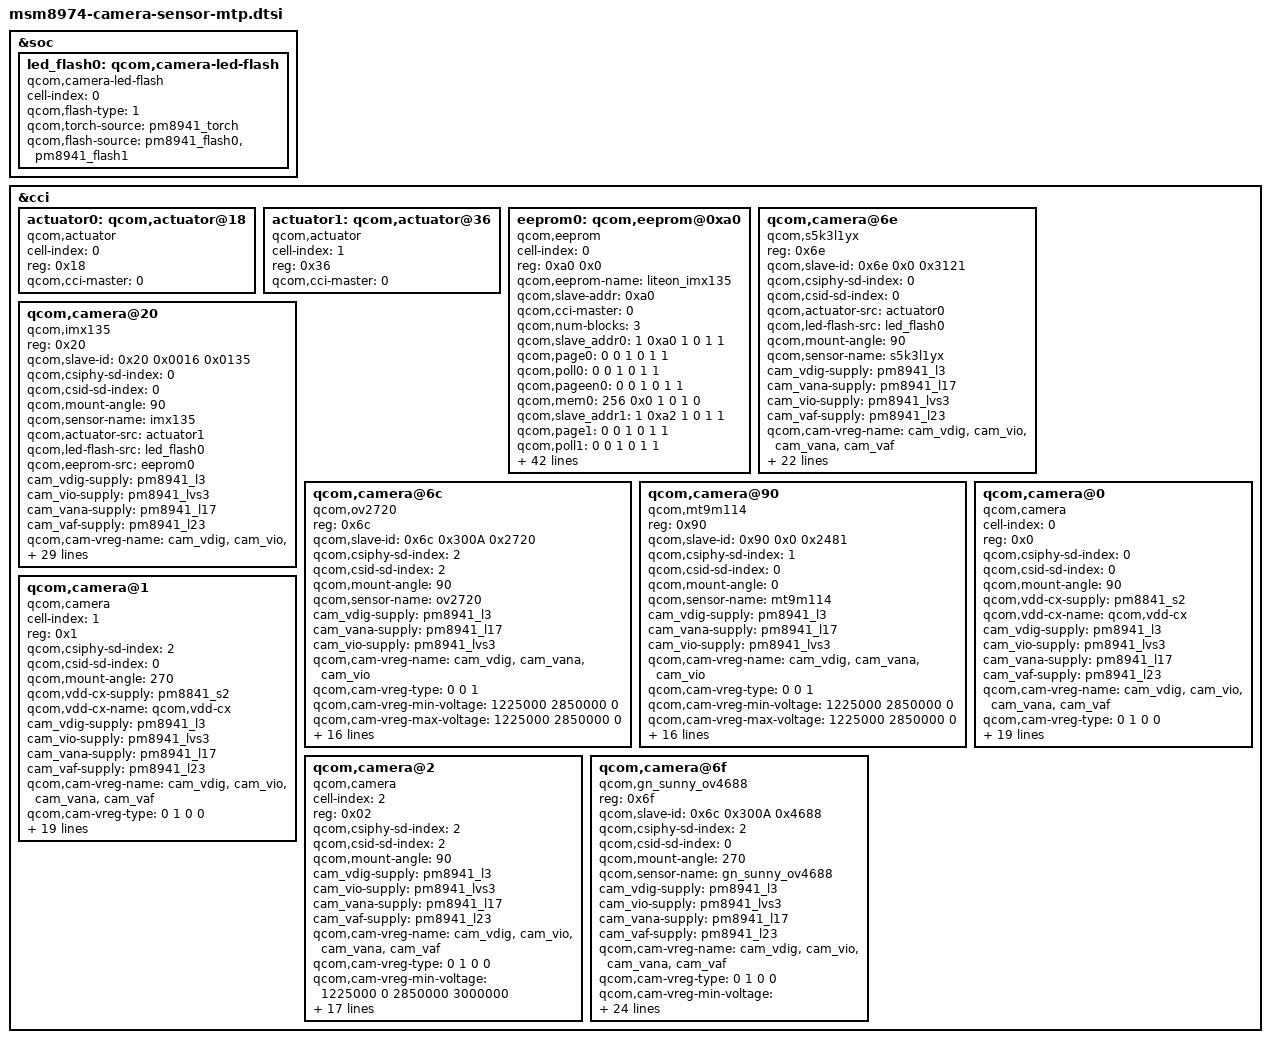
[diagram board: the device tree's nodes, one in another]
/*
 * Copyright (c) 2012-2014, The Linux Foundation. All rights reserved.
 *
 * This program is free software; you can redistribute it and/or modify
 * it under the terms of the GNU General Public License version 2 and
 * only version 2 as published by the Free Software Foundation.
 *
 * This program is distributed in the hope that it will be useful,
 * but WITHOUT ANY WARRANTY; without even the implied warranty of
 * MERCHANTABILITY or FITNESS FOR A PARTICULAR PURPOSE.  See the
 * GNU General Public License for more details.
 */

&soc {
	led_flash0: qcom,camera-led-flash {
		cell-index = <0>;
		compatible = "qcom,camera-led-flash";
		qcom,flash-type = <1>;
		qcom,torch-source = <&pm8941_torch>;
		qcom,flash-source = <&pm8941_flash0 &pm8941_flash1>;
	};
};

&cci {

	actuator0: qcom,actuator@18 {
		cell-index = <0>;
		reg = <0x18>;
		compatible = "qcom,actuator";
		qcom,cci-master = <0>;
	};

	actuator1: qcom,actuator@36 {
		cell-index = <1>;
		reg = <0x36>;
		compatible = "qcom,actuator";
		qcom,cci-master = <0>;
	};
 //add by gionee chenqiang for eeprom 20140617 begin
        eeprom0: qcom,eeprom@0xa0 {
		cell-index = <0>;
		reg = <0xa0 0x0>;
		qcom,eeprom-name = "liteon_imx135";
		compatible = "qcom,eeprom";
		qcom,slave-addr = <0xa0>;
		qcom,cci-master = <0>;
		qcom,num-blocks = <3>;

		qcom,slave_addr0 = <1 0xa0 1 0 1 1>;
		qcom,page0 = <0 0 1 0 1 1>;
		qcom,poll0 = <0 0 1 0 1 1>;
		qcom,pageen0 = <0 0 1 0 1 1>;
		qcom,mem0 = <256 0x0 1 0 1 0>;

		qcom,slave_addr1 = <1 0xa2 1 0 1 1>;
		qcom,page1 = <0 0 1 0 1 1>;
		qcom,poll1 = <0 0 1 0 1 1>;
		qcom,pageen1 = <0 0 1 0 1 1>;
		qcom,mem1 = <256 0 1 0 1 0>;

		qcom,slave_addr2 = <1 0xa4 1 0 1 1>;
		qcom,page2 = <0 0 1 0 1 1>;
		qcom,poll2 = <0 0 1 0 1 1>;
		qcom,pageen2 = <0 0 1 0 1 1>;
		qcom,mem2 = <82 0 1 0 1 0>;

		cam_vdig-supply = <&pm8941_l3>;
		cam_vio-supply = <&pm8941_lvs3>;
		cam_vana-supply = <&pm8941_l17>;
		cam_vaf-supply = <&pm8941_l23>;
		qcom,cam-vreg-name = "cam_vdig", "cam_vio", "cam_vana",  "cam_vaf";
		qcom,cam-vreg-type = <0 1 0 0>;
		qcom,cam-vreg-min-voltage = <1225000  0 2700000 3000000>;
		qcom,cam-vreg-max-voltage = <1225000  0 2700000 3000000>;
		qcom,cam-vreg-op-mode = <105000 0 80000 100000>;

		qcom,gpio-no-mux = <0>;

               gpios = <&msmgpio 15 0>,
			<&msmgpio 90 0>,
			<&msmgpio 91 0>,
			<&msmgpio 26 0>,
			<&msmgpio 89 0>;
		qcom,gpio-reset = <1>;
		qcom,gpio-standby = <2>;
                qcom,gpio-vdig = <3>;
                qcom,gpio-af-pwdm = <4>;
		qcom,gpio-req-tbl-num = <0 1 2 3 4>;
		qcom,gpio-req-tbl-flags = <1 0 0 0 0>;
		qcom,gpio-req-tbl-label = "CAMIF_MCLK",
					  "CAM_RESET",
					  "CAM_STANDBY",
					  "CAM_VDIG",
					  "CAM_AF_PWDM";
		qcom,gpio-set-tbl-num = <1 1>;
		qcom,gpio-set-tbl-flags = <0 2>;
		qcom,gpio-set-tbl-delay = <1000 30000>;


                qcom,cam-power-seq-type = "sensor_vreg","sensor_vreg","sensor_vreg",
                                          "sensor_gpio","sensor_gpio";
		qcom,cam-power-seq-val =  "cam_vdig", "cam_vana", "cam_vio",
                                          "sensor_gpio_standby","sensor_gpio_reset";
		qcom,cam-power-seq-cfg-val = <1 1 1 1  1>;
		qcom,cam-power-seq-delay   = <5 1 5 20 20>;	
	};
 //add by gionee chenqiang for eeprom 20140617 end
	qcom,camera@6e {
		compatible = "qcom,s5k3l1yx";
		reg = <0x6e>;
		qcom,slave-id = <0x6e 0x0 0x3121>;
		qcom,csiphy-sd-index = <0>;
		qcom,csid-sd-index = <0>;
		qcom,actuator-src = <&actuator0>;
		qcom,led-flash-src = <&led_flash0>;
		qcom,mount-angle = <90>;
		qcom,sensor-name = "s5k3l1yx";
		cam_vdig-supply = <&pm8941_l3>;
		cam_vana-supply = <&pm8941_l17>;
		cam_vio-supply = <&pm8941_lvs3>;
		cam_vaf-supply = <&pm8941_l23>;
		qcom,cam-vreg-name = "cam_vdig", "cam_vio", "cam_vana",
				     "cam_vaf";
		qcom,cam-vreg-type = <0 1 0 0>;
		qcom,cam-vreg-min-voltage = <1225000 0 2850000 3000000>;
		qcom,cam-vreg-max-voltage = <1225000 0 2850000 3000000>;
		qcom,cam-vreg-op-mode = <105000 0 80000 100000>;
		qcom,gpio-no-mux = <0>;
		gpios = <&msmgpio 15 0>,
			<&msmgpio 90 0>,
			<&msmgpio 89 0>;
		qcom,gpio-reset = <1>;
		qcom,gpio-standby = <2>;
		qcom,gpio-req-tbl-num = <0 1 2>;
		qcom,gpio-req-tbl-flags = <1 0 0>;
		qcom,gpio-req-tbl-label = "CAMIF_MCLK",
					  "CAM_RESET1",
					  "CAM_STANDBY";
		qcom,gpio-set-tbl-num = <1 1>;
		qcom,gpio-set-tbl-flags = <0 2>;
		qcom,gpio-set-tbl-delay = <1000 30000>;
		qcom,csi-lane-assign = <0x4320>;
		qcom,csi-lane-mask = <0x1F>;
		qcom,sensor-position = <0>;
		qcom,sensor-mode = <1>;
		qcom,cci-master = <0>;
		status = "ok";
	};
    qcom,camera@20 {
		compatible = "qcom,imx135";
		reg = <0x20>;
		qcom,slave-id = <0x20 0x0016 0x0135>;
		qcom,csiphy-sd-index = <0>;
		qcom,csid-sd-index = <0>;
		qcom,mount-angle = <90>;
		qcom,sensor-name = "imx135";
		qcom,actuator-src = <&actuator1>;
		qcom,led-flash-src = <&led_flash0>;
		qcom,eeprom-src = <&eeprom0>;  //add by gionee chenqiang for eeprom 20140617 
		cam_vdig-supply = <&pm8941_l3>;
		cam_vio-supply = <&pm8941_lvs3>;
		cam_vana-supply = <&pm8941_l17>;
		cam_vaf-supply = <&pm8941_l23>;
		qcom,cam-vreg-name = "cam_vdig", "cam_vio", "cam_vana",  "cam_vaf";
		qcom,cam-vreg-type = <0 1 0 0>;
		qcom,cam-vreg-min-voltage = <1225000  0 2700000 3000000>;
		qcom,cam-vreg-max-voltage = <1225000  0 2700000 3000000>;
		qcom,cam-vreg-op-mode = <105000 0 80000 100000>;

		qcom,gpio-no-mux = <0>;

               gpios = <&msmgpio 15 0>,
			<&msmgpio 90 0>,
			<&msmgpio 91 0>,
			<&msmgpio 26 0>,
			<&msmgpio 89 0>,
			<&msmgpio 56 0>; //add by gionee zhaocuiqin for CR01324957 20140721 begin
		qcom,gpio-reset = <1>;
		qcom,gpio-standby = <2>;
                qcom,gpio-vdig = <3>;
                qcom,gpio-af-pwdm = <4>;
                qcom,gpio-vaf = <5>;
		qcom,gpio-req-tbl-num = <0 1 2 3 4 5>;
		qcom,gpio-req-tbl-flags = <1 0 0 0 0 0>;
		qcom,gpio-req-tbl-label = "CAMIF_MCLK",
					  "CAM_RESET",
					  "CAM_STANDBY",
					  "CAM_VDIG",
					  "CAM_AF_PWDM",
					  "CAM_VAF";
		qcom,gpio-set-tbl-num = <1 1>;
		qcom,gpio-set-tbl-flags = <0 2>;
		qcom,gpio-set-tbl-delay = <1000 30000>;

		qcom,csi-lane-assign = <0x4320>;
		qcom,csi-lane-mask = <0x1F>;
		qcom,sensor-position = <0>;
		qcom,sensor-mode = <0>;
	        qcom,sensor-type = <0>;
		qcom,cci-master = <0>;
		status = "ok";
	};


	qcom,camera@6c {
		compatible = "qcom,ov2720";
		reg = <0x6c>;
		qcom,slave-id = <0x6c 0x300A 0x2720>;
		qcom,csiphy-sd-index = <2>;
		qcom,csid-sd-index = <2>;
		qcom,mount-angle = <90>;
		qcom,sensor-name = "ov2720";
		cam_vdig-supply = <&pm8941_l3>;
		cam_vana-supply = <&pm8941_l17>;
		cam_vio-supply = <&pm8941_lvs3>;
		qcom,cam-vreg-name = "cam_vdig", "cam_vana", "cam_vio";
		qcom,cam-vreg-type = <0 0 1>;
		qcom,cam-vreg-min-voltage = <1225000 2850000 0>;
		qcom,cam-vreg-max-voltage = <1225000 2850000 0>;
		qcom,cam-vreg-op-mode = <105000 80000 0>;
		qcom,gpio-no-mux = <0>;
		gpios = <&msmgpio 17 0>,
			<&msmgpio 18 0>;
		qcom,gpio-reset = <1>;
		qcom,gpio-req-tbl-num = <0 1>;
		qcom,gpio-req-tbl-flags = <1 0>;
		qcom,gpio-req-tbl-label = "CAMIF_MCLK",
					  "CAM_RESET1";
		qcom,gpio-set-tbl-num = <1 1>;
		qcom,gpio-set-tbl-flags = <0 2>;
		qcom,gpio-set-tbl-delay = <1000 4000>;
		qcom,csi-lane-assign = <0x4320>;
		qcom,csi-lane-mask = <0x7>;
		qcom,sensor-position = <1>;
		qcom,sensor-mode = <1>;
		qcom,cci-master = <1>;
		status = "ok";
	};

	qcom,camera@90 {
		compatible = "qcom,mt9m114";
		reg = <0x90>;
		qcom,slave-id = <0x90 0x0 0x2481>;
		qcom,csiphy-sd-index = <1>;
		qcom,csid-sd-index = <0>;
		qcom,mount-angle = <0>;
		qcom,sensor-name = "mt9m114";
		cam_vdig-supply = <&pm8941_l3>;
		cam_vana-supply = <&pm8941_l17>;
		cam_vio-supply = <&pm8941_lvs3>;
		qcom,cam-vreg-name = "cam_vdig", "cam_vana", "cam_vio";
		qcom,cam-vreg-type = <0 0 1>;
		qcom,cam-vreg-min-voltage = <1225000 2850000 0>;
		qcom,cam-vreg-max-voltage = <1225000 2850000 0>;
		qcom,cam-vreg-op-mode = <105000 80000 0>;
		qcom,gpio-no-mux = <0>;
		gpios = <&msmgpio 16 0>,
			<&msmgpio 92 0>;
		qcom,gpio-reset = <1>;
		qcom,gpio-req-tbl-num = <0 1>;
		qcom,gpio-req-tbl-flags = <1 0>;
		qcom,gpio-req-tbl-label = "CAMIF_MCLK",
					  "CAM_RESET1";
		qcom,gpio-set-tbl-num = <1 1>;
		qcom,gpio-set-tbl-flags = <0 2>;
		qcom,gpio-set-tbl-delay = <1000 4000>;
		qcom,csi-lane-assign = <0x4320>;
		qcom,csi-lane-mask = <0x3>;
		qcom,sensor-position = <1>;
		qcom,sensor-mode = <1>;
		qcom,cci-master = <0>;
	};
	qcom,camera@0 {
		cell-index = <0>;
		compatible = "qcom,camera";
		reg = <0x0>;
		qcom,csiphy-sd-index = <0>;
		qcom,csid-sd-index = <0>;
		qcom,mount-angle = <90>;
		//qcom,actuator-src = <&actuator0>;
		//qcom,led-flash-src = <&led_flash0>;
		qcom,vdd-cx-supply = <&pm8841_s2>;
		qcom,vdd-cx-name = "qcom,vdd-cx";
/*   //deleted by chenqiang for camera 0
		qcom,cam-vreg-name = "cam_vdig", "cam_vio", "cam_vana",
				     "cam_vaf";
		qcom,cam-vreg-type = <0 1 0 0>;
		qcom,cam-vreg-min-voltage = <1225000 0 2850000 3000000>;
		qcom,cam-vreg-max-voltage = <1225000 0 2850000 3000000>;
		qcom,cam-vreg-op-mode = <105000 0 80000 100000>;



		gpios = <&msmgpio 15 0>,
			<&msmgpio 90 0>,
			<&msmgpio 89 0>;
		qcom,gpio-reset = <1>;
		qcom,gpio-standby = <2>;
		qcom,gpio-req-tbl-num = <0 1 2>;
		qcom,gpio-req-tbl-flags = <1 0 0>;
		qcom,gpio-req-tbl-label = "CAMIF_MCLK",
					  "CAM_RESET1",
					  "CAM_STANDBY";
*/
		cam_vdig-supply = <&pm8941_l3>;
		cam_vio-supply = <&pm8941_lvs3>;
		cam_vana-supply = <&pm8941_l17>;
		cam_vaf-supply = <&pm8941_l23>;
		qcom,cam-vreg-name = "cam_vdig", "cam_vio", "cam_vana",  "cam_vaf";
		qcom,cam-vreg-type = <0 1 0 0>;
		qcom,cam-vreg-min-voltage = <1225000  0 2700000 3000000>;
		qcom,cam-vreg-max-voltage = <1225000  0 2700000 3000000>;
		qcom,cam-vreg-op-mode = <105000 0 80000 100000>;
                gpios = <&msmgpio 15 0>,
			<&msmgpio 90 0>,
			<&msmgpio 91 0>,
			<&msmgpio 26 0>,
			<&msmgpio 89 0>;
		qcom,gpio-reset = <1>;
		qcom,gpio-standby = <2>;
                qcom,gpio-vdig = <3>;
                qcom,gpio-af-pwdm = <4>;
		qcom,gpio-req-tbl-num = <0 1 2 3 4>;
		qcom,gpio-req-tbl-flags = <1 0 0 0 0>;
		qcom,gpio-req-tbl-label = "CAMIF_MCLK",
					  "CAM_RESET",
					  "CAM_STANDBY",
					  "CAM_VDIG",
					  "CAM_AF_PWDM";
//add by chenqiang  20140420
		qcom,sensor-position = <0>;
		qcom,sensor-mode = <0>;
		qcom,cci-master = <0>;
		status = "ok";
	};
	qcom,camera@1 {
		cell-index = <1>;
		compatible = "qcom,camera";
		reg = <0x1>;
		qcom,csiphy-sd-index = <2>;
		qcom,csid-sd-index = <0>;
		qcom,mount-angle = <270>;
		qcom,vdd-cx-supply = <&pm8841_s2>;
		qcom,vdd-cx-name = "qcom,vdd-cx";
/* modified by chenqiang 20140420
		cam_vdig-supply = <&pm8941_l3>;
		cam_vana-supply = <&pm8941_l17>;
		cam_vio-supply = <&pm8941_lvs3>;
		qcom,cam-vreg-name = "cam_vdig", "cam_vio", "cam_vana",
				     "cam_vaf";
		qcom,cam-vreg-type = <0 1 0 0>;
		qcom,cam-vreg-min-voltage = <1225000 0 2850000 3000000>;
		qcom,cam-vreg-max-voltage = <1225000 0 2850000 3000000>;
		qcom,cam-vreg-op-mode = <105000 0 80000 100000>;
		gpios = <&msmgpio 17 0>,
			<&msmgpio 18 0>;
		qcom,gpio-reset = <1>;
		qcom,gpio-req-tbl-num = <0 1>;
		qcom,gpio-req-tbl-flags = <1 0>;
		qcom,gpio-req-tbl-label = "CAMIF_MCLK",
					  "CAM_RESET1";
*/

		cam_vdig-supply = <&pm8941_l3>;
		cam_vio-supply = <&pm8941_lvs3>;
		cam_vana-supply = <&pm8941_l17>;
		cam_vaf-supply = <&pm8941_l23>;
		qcom,cam-vreg-name = "cam_vdig", "cam_vio", "cam_vana",  "cam_vaf";
		qcom,cam-vreg-type = <0 1 0 0>;
		qcom,cam-vreg-min-voltage = <1225000  0 2850000 3000000>;
		qcom,cam-vreg-max-voltage = <1225000  0 2850000 3000000>;
		qcom,cam-vreg-op-mode = <105000 0 80000 100000>;
		gpios = <&msmgpio 17 0>,
			<&msmgpio 18 0>,
			<&msmgpio 23 0>,
			<&msmgpio 26 0>,
			<&msmgpio 25 0>;
		qcom,gpio-reset = <1>;
		qcom,gpio-standby = <2>;
                qcom,gpio-vdig = <3>;
                qcom,gpio-af-pwdm = <4>;
		qcom,gpio-req-tbl-num = <0 1 2 3 4>;
		qcom,gpio-req-tbl-flags = <1 0 0 0 0 >;
		qcom,gpio-req-tbl-label = "CAMIF_MCLK",
					  "CAM_RESET1",
					  "CAM_STANDBY1",
					  "CAM_VDIG",
					  "CAM_AF_PWDM1";
//add by chenqiang 20140420
		qcom,sensor-position = <1>;
		qcom,sensor-mode = <0>;
		qcom,cci-master = <1>;
		status = "ok";
	};

	qcom,camera@2 {
		cell-index = <2>;
		compatible = "qcom,camera";
		reg = <0x02>;
		qcom,csiphy-sd-index = <2>;
		qcom,csid-sd-index = <2>;
		qcom,mount-angle = <90>;
/*
		cam_vdig-supply = <&pm8941_l3>;
		cam_vana-supply = <&pm8941_l17>;
		cam_vio-supply = <&pm8941_lvs3>;
		qcom,cam-vreg-name = "cam_vdig", "cam_vana", "cam_vio";
		qcom,cam-vreg-type = <0 0 1>;
		qcom,cam-vreg-min-voltage = <1225000 2850000 0>;
		qcom,cam-vreg-max-voltage = <1225000 2850000 0>;
		qcom,cam-vreg-op-mode = <105000 80000 0>;
		qcom,gpio-no-mux = <0>;
		gpios = <&msmgpio 17 0>,
			<&msmgpio 18 0>;
		qcom,gpio-reset = <1>;
		qcom,gpio-req-tbl-num = <0 1>;
		qcom,gpio-req-tbl-flags = <1 0>;
		qcom,gpio-req-tbl-label = "CAMIF_MCLK",
					  "CAM_RESET1";
*/
		cam_vdig-supply = <&pm8941_l3>;
		cam_vio-supply = <&pm8941_lvs3>;
		cam_vana-supply = <&pm8941_l17>;
		cam_vaf-supply = <&pm8941_l23>;
		qcom,cam-vreg-name = "cam_vdig", "cam_vio", "cam_vana",  "cam_vaf";
		qcom,cam-vreg-type = <0 1 0 0>;
		qcom,cam-vreg-min-voltage = <1225000  0 2850000 3000000>;
		qcom,cam-vreg-max-voltage = <1225000  0 2850000 3000000>;
		qcom,cam-vreg-op-mode = <105000 0 80000 100000>;
		gpios = <&msmgpio 17 0>,
			<&msmgpio 18 0>,
			<&msmgpio 23 0>,
			<&msmgpio 26 0>,
			<&msmgpio 25 0>;
		qcom,gpio-reset = <1>;
		qcom,gpio-standby = <2>;
                qcom,gpio-vdig = <3>;
                qcom,gpio-af-pwdm = <4>;
		qcom,gpio-req-tbl-num = <0 1 2 3 4>;
		qcom,gpio-req-tbl-flags = <1 0 0 0 0 >;
		qcom,gpio-req-tbl-label = "CAMIF_MCLK",
					  "CAM_RESET1",
					  "CAM_STANDBY1",
					  "CAM_VDIG",
					  "CAM_AF_PWDM1";
//add by chenqiang 20140420
		qcom,sensor-position = <1>;
		qcom,sensor-mode = <0>;
		qcom,cci-master = <1>;
		status = "ok";
	};
qcom,camera@6f {
		compatible = "qcom,gn_sunny_ov4688";
		reg = <0x6f>;
		qcom,slave-id = <0x6c 0x300A 0x4688>;
		qcom,csiphy-sd-index = <2>;
		qcom,csid-sd-index = <0>;
		qcom,mount-angle = <270>;
		qcom,sensor-name = "gn_sunny_ov4688";
		cam_vdig-supply = <&pm8941_l3>;
		cam_vio-supply = <&pm8941_lvs3>;
		cam_vana-supply = <&pm8941_l17>;
		cam_vaf-supply = <&pm8941_l23>;
		qcom,cam-vreg-name = "cam_vdig", "cam_vio", "cam_vana",  "cam_vaf";
		qcom,cam-vreg-type = <0 1 0 0>;
		qcom,cam-vreg-min-voltage = <1225000  0 2850000 3000000>;
		qcom,cam-vreg-max-voltage = <1225000  0 2850000 3000000>;
		qcom,cam-vreg-op-mode = <105000 0 80000 100000>;
		qcom,gpio-no-mux = <0>;
		gpios = <&msmgpio 17 0>,
			<&msmgpio 18 0>,
			<&msmgpio 23 0>,
			<&msmgpio 26 0>,
			<&msmgpio 25 0>;
		qcom,gpio-reset = <1>;
		qcom,gpio-standby = <2>;
                qcom,gpio-vdig = <3>;
                qcom,gpio-af-pwdm = <4>;
		qcom,gpio-req-tbl-num = <0 1 2 3 4>;
		qcom,gpio-req-tbl-flags = <1 0 0 0 0 >;
		qcom,gpio-req-tbl-label = "CAMIF_MCLK",
					  "CAM_RESET1",
					  "CAM_STANDBY1",
					  "CAM_VDIG",
					  "CAM_AF_PWDM1";
		qcom,gpio-set-tbl-num = <2 1 1 >;
		qcom,gpio-set-tbl-flags = <2 0 2>;
		qcom,gpio-set-tbl-delay = <10000 1000 4000>;
		qcom,csi-lane-assign = <0x4320>;
		qcom,csi-lane-mask = <0x1f>;
		qcom,sensor-position = <1>;
		qcom,sensor-mode = <1>;
		qcom,cci-master = <1>;
		status = "ok";
	};
};
